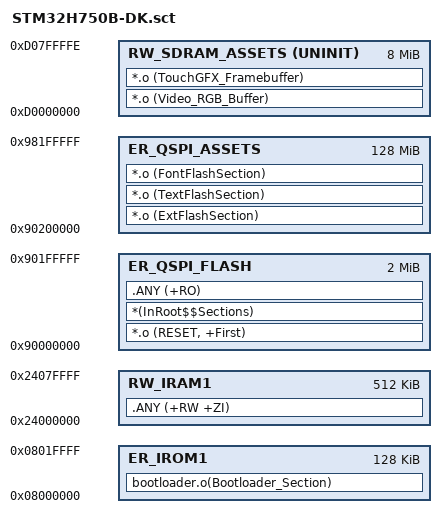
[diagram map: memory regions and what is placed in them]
; *************************************************************
; *** Scatter-Loading Description File generated by uVision ***
; *************************************************************

LR_IROM1 0x08000000 0x00020000  {    ; load region size_region
  ER_IROM1 0x08000000 0x00020000  {  ; load address = execution address
    bootloader.o(Bootloader_Section)
  }
  RW_IRAM1 0x24000000 0x00080000  {  ; RW data
   .ANY (+RW +ZI)
  }
}

LR_QSPI_FLASH 0x90000000 0x00200000  {    ; load region size_region
  ER_QSPI_FLASH 0x90000000 0x00200000  {  ; load address = execution address
   *.o (RESET, +First)
   *(InRoot$$Sections)
   .ANY (+RO)
  }
}

LR_QSPI_ASSETS 0x90200000 0x08000000  {    ; load region size_region
  ER_QSPI_ASSETS 0x90200000 0x08000000  {  ; load address = execution address
   *.o (ExtFlashSection)
   *.o (TextFlashSection)
   *.o (FontFlashSection)
  }
}

LR_SDRAM_ASSETS 0xD0000000 0x007FFFFF {
    RW_SDRAM_ASSETS 0xD0000000 UNINIT 0x007FFFFF {
    *.o (Video_RGB_Buffer)
    *.o (TouchGFX_Framebuffer)
  }
}

